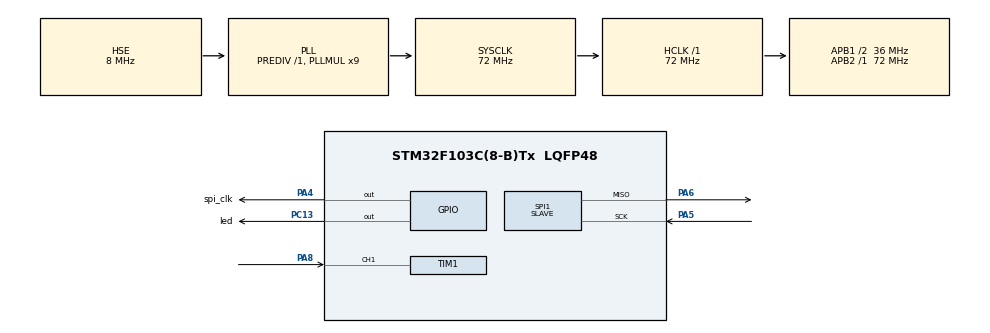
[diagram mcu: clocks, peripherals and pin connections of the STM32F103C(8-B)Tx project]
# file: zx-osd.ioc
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Dma.Request0=SPI1_TX
Dma.SPI1_TX.0.Direction=DMA_MEMORY_TO_PERIPH
Dma.SPI1_TX.0.Instance=DMA1_Channel3
Dma.SPI1_TX.0.MemDataAlignment=DMA_MDATAALIGN_BYTE
Dma.SPI1_TX.0.MemInc=DMA_MINC_ENABLE
Dma.SPI1_TX.0.Mode=DMA_CIRCULAR
Dma.SPI1_TX.0.PeriphDataAlignment=DMA_PDATAALIGN_BYTE
Dma.SPI1_TX.0.PeriphInc=DMA_PINC_DISABLE
Dma.SPI1_TX.0.Priority=DMA_PRIORITY_LOW
Mcu.Family=STM32F1
Mcu.Name=STM32F103C(8-B)Tx
Mcu.Package=LQFP48
NVIC.DMA1_Channel3_IRQn=true\:0\:0\:false\:false\:true\:false\:true\:true
NVIC.PriorityGroup=NVIC_PRIORITYGROUP_4
NVIC.TIM1_BRK_IRQn=true\:0\:0\:false\:false\:true\:true\:true\:true
NVIC.TIM1_CC_IRQn=true\:0\:0\:false\:false\:true\:true\:true\:true
NVIC.TIM1_TRG_COM_IRQn=true\:0\:0\:false\:false\:true\:true\:true\:true
NVIC.TIM1_UP_IRQn=true\:0\:0\:false\:false\:true\:true\:true\:true
PA13.Mode=Serial_Wire
PA13.Signal=SYS_JTMS-SWDIO
PA14.Mode=Serial_Wire
PA14.Signal=SYS_JTCK-SWCLK
PA4.GPIO_Label=spi_clk
PA4.Signal=GPIO_Output
PA5.Mode=TX_Only_Simplex_Unidirect_Slave
PA5.Signal=SPI1_SCK
PA6.Mode=TX_Only_Simplex_Unidirect_Slave
PA6.Signal=SPI1_MISO
PA8.Signal=S_TIM1_CH1
PC13-TAMPER-RTC.GPIO_Label=led
PC13-TAMPER-RTC.Signal=GPIO_Output
PD0-OSC_IN.Mode=HSE-External-Oscillator
PD0-OSC_IN.Signal=RCC_OSC_IN
PD1-OSC_OUT.Mode=HSE-External-Oscillator
PD1-OSC_OUT.Signal=RCC_OSC_OUT
ProjectManager.HeapSize=0x200
ProjectManager.StackSize=0x400
ProjectManager.TargetToolchain=STM32CubeIDE
RCC.AHBFreq_Value=72000000
RCC.APB1CLKDivider=RCC_HCLK_DIV2
RCC.APB1Freq_Value=36000000
RCC.APB1TimFreq_Value=72000000
RCC.APB2Freq_Value=72000000
RCC.APB2TimFreq_Value=72000000
RCC.HCLKFreq_Value=72000000
RCC.PLLMUL=RCC_PLL_MUL9
RCC.PLLSourceVirtual=RCC_PLLSOURCE_HSE
RCC.RCC_MCOSource=RCC_MCO1SOURCE_HSE
RCC.SYSCLKFreq_VALUE=72000000
RCC.SYSCLKSource=RCC_SYSCLKSOURCE_PLLCLK
RCC.USBFreq_Value=72000000
SH.S_TIM1_CH1.0=TIM1_CH1,TriggerSource_TI1ED
SPI1.Direction=SPI_DIRECTION_2LINES
SPI1.Mode=SPI_MODE_SLAVE
SPI1.VirtualType=VM_SLAVE
TIM1.Period=1000
board=custom

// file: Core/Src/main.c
/* USER CODE BEGIN Header */
/**
  ******************************************************************************
  * @file           : main.c
  * @brief          : Main program body
  ******************************************************************************
  * @attention
  *
  * Copyright (c) 2024 STMicroelectronics.
  * All rights reserved.
  *
  * This software is licensed under terms that can be found in the LICENSE file
  * in the root directory of this software component.
  * If no LICENSE file comes with this software, it is provided AS-IS.
  *
  ******************************************************************************
  */
/* USER CODE END Header */
#include "main.h"
#include "dma.h"
#include "spi.h"
#include "tim.h"
#include "gpio.h"

/* USER CODE BEGIN Includes */
#include "function.h"
/* USER CODE END Includes */

void SystemClock_Config(void);

int main(void)
{

  /* MCU Configuration--------------------------------------------------------*/

  /* Reset of all peripherals, Initializes the Flash interface and the Systick. */
  HAL_Init();

  /* Configure the system clock */
  SystemClock_Config();

  /* Initialize all configured peripherals */
  MX_GPIO_Init();
  MX_DMA_Init();
  MX_SPI1_Init();
  MX_TIM1_Init();

  /* Infinite loop */
  while (1)
  {

    /* USER CODE BEGIN 3 */
//  	function();
  }
  /* USER CODE END 3 */
}

void SystemClock_Config(void)
{
  RCC_OscInitTypeDef RCC_OscInitStruct = {0};
  RCC_ClkInitTypeDef RCC_ClkInitStruct = {0};

  /** Initializes the RCC Oscillators according to the specified parameters
  * in the RCC_OscInitTypeDef structure.
  */
  RCC_OscInitStruct.OscillatorType = RCC_OSCILLATORTYPE_HSE;
  RCC_OscInitStruct.HSEState = RCC_HSE_ON;
  RCC_OscInitStruct.HSEPredivValue = RCC_HSE_PREDIV_DIV1;
  RCC_OscInitStruct.HSIState = RCC_HSI_ON;
  RCC_OscInitStruct.PLL.PLLState = RCC_PLL_ON;
  RCC_OscInitStruct.PLL.PLLSource = RCC_PLLSOURCE_HSE;
  RCC_OscInitStruct.PLL.PLLMUL = RCC_PLL_MUL9;
  if (HAL_RCC_OscConfig(&RCC_OscInitStruct) != HAL_OK)
  {
    Error_Handler();
  }

  /** Initializes the CPU, AHB and APB buses clocks
  */
  RCC_ClkInitStruct.ClockType = RCC_CLOCKTYPE_HCLK|RCC_CLOCKTYPE_SYSCLK
                              |RCC_CLOCKTYPE_PCLK1|RCC_CLOCKTYPE_PCLK2;
  RCC_ClkInitStruct.SYSCLKSource = RCC_SYSCLKSOURCE_PLLCLK;
  RCC_ClkInitStruct.AHBCLKDivider = RCC_SYSCLK_DIV1;
  RCC_ClkInitStruct.APB1CLKDivider = RCC_HCLK_DIV2;
  RCC_ClkInitStruct.APB2CLKDivider = RCC_HCLK_DIV1;

  if (HAL_RCC_ClockConfig(&RCC_ClkInitStruct, FLASH_LATENCY_2) != HAL_OK)
  {
    Error_Handler();
  }
}

void Error_Handler(void)
{
  __disable_irq();
  while (1)
  {
  }
}
